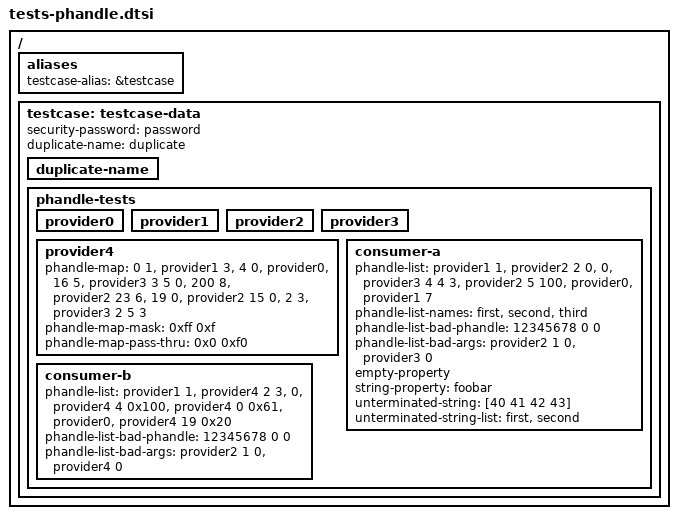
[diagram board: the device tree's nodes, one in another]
// SPDX-License-Identifier: GPL-2.0

/ {
	aliases {
		testcase-alias = &testcase;
	};

	testcase: testcase-data {
		security-password = "password";
		duplicate-name = "duplicate";

		duplicate-name { };

		phandle-tests {
			provider0: provider0 {
				#phandle-cells = <0>;
			};

			provider1: provider1 {
				#phandle-cells = <1>;
			};

			provider2: provider2 {
				#phandle-cells = <2>;
			};

			provider3: provider3 {
				#phandle-cells = <3>;
			};

			provider4: provider4 {
				#phandle-cells = <2>;
				phandle-map = <0 1 &provider1 3>,
					      <4 0 &provider0>,
					      <16 5 &provider3 3 5 0>,
					      <200 8 &provider2 23 6>,
					      <19 0 &provider2 15 0>,
					      <2 3 &provider3 2 5 3>;
				phandle-map-mask = <0xff 0xf>;
				phandle-map-pass-thru = <0x0 0xf0>;
			};

			consumer-a {
				phandle-list =	<&provider1 1>,
						<&provider2 2 0>,
						<0>,
						<&provider3 4 4 3>,
						<&provider2 5 100>,
						<&provider0>,
						<&provider1 7>;
				phandle-list-names = "first", "second", "third";

				phandle-list-bad-phandle = <12345678 0 0>;
				phandle-list-bad-args = <&provider2 1 0>,
							<&provider3 0>;
				empty-property;
				string-property = "foobar";
				unterminated-string = [40 41 42 43];
				unterminated-string-list = "first", "second", [40 41 42 43];
			};

			consumer-b {
				phandle-list =	<&provider1 1>,
						<&provider4 2 3>,
						<0>,
						<&provider4 4 0x100>,
						<&provider4 0 0x61>,
						<&provider0>,
						<&provider4 19 0x20>;
				phandle-list-bad-phandle = <12345678 0 0>;
				phandle-list-bad-args = <&provider2 1 0>,
							<&provider4 0>;
			};
		};
	};
};
